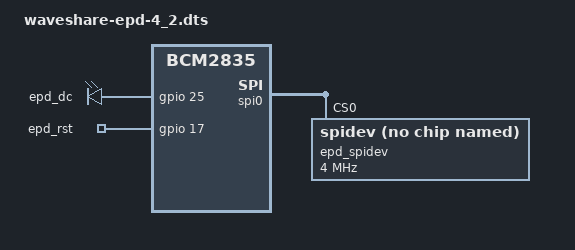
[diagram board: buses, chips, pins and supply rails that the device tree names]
/dts-v1/;
/plugin/;

/*
 * Device Tree Overlay for Waveshare 4.2" E-Paper Display
 *
 * This overlay configures SPI0 and GPIO pins for the Waveshare 4.2" e-paper
 * display module (Rev 2.2) with UC8176/IL0398 controller.
 *
 * Hardware Requirements:
 * - Waveshare 4.2" E-Paper Module (400x300, B/W)
 * - Raspberry Pi Zero W
 *
 * Pin Connections:
 * - VCC:  Pin 1  (3.3V)
 * - GND:  Pin 6  (GND)
 * - DIN:  Pin 19 (GPIO 10 / MOSI)
 * - CLK:  Pin 23 (GPIO 11 / SCLK)
 * - CS:   Pin 24 (GPIO 8  / CE0)
 * - DC:   Pin 22 (GPIO 25)
 * - RST:  Pin 11 (GPIO 17)
 * - BUSY: Pin 18 (GPIO 24)
 *
 * References:
 * - https://www.waveshare.com/wiki/4.2inch_e-Paper_Module
 * - UC8176/IL0398 Controller Datasheet
 */

/ {
	compatible = "brcm,bcm2835";

	fragment@0 {
		target = <&spi0>;
		__overlay__ {
			status = "okay";
			#address-cells = <1>;
			#size-cells = <0>;

			/* SPI0 chip select 0 configuration */
			epd_spidev: spidev@0 {
				compatible = "spidev";
				reg = <0>;	/* CE0 (GPIO 8) */

				/*
				 * SPI frequency: 4 MHz for reliable operation
				 * Display supports up to 10 MHz, but 4 MHz provides
				 * better reliability with longer wires
				 */
				spi-max-frequency = <4000000>;

				/*
				 * SPI Mode 0: CPOL=0, CPHA=0
				 * Clock idle state: LOW
				 * Data sampled on rising edge
				 */
				spi-cpol = <0>;
				spi-cpha = <0>;
			};
		};
	};

	fragment@1 {
		target = <&gpio>;
		__overlay__ {
			epd_pins: epd_pins {
				brcm,pins = <17 24 25>;  /* RST, BUSY, DC */
				brcm,function = <1 0 1>; /* OUT, IN, OUT */
				brcm,pull = <0 2 0>;     /* NONE, UP, NONE */
			};
		};
	};

	/*
	 * Define GPIO pins for e-paper display control
	 * These will be accessed from userspace via /sys/class/gpio or libgpiod
	 */
	fragment@2 {
		target-path = "/";
		__overlay__ {
			epd_gpios {
				compatible = "gpio-leds";
				pinctrl-names = "default";
				pinctrl-0 = <&epd_pins>;

				/*
				 * GPIO 25 - Data/Command (DC)
				 * LOW = Command mode
				 * HIGH = Data mode
				 */
				dc {
					label = "epd_dc";
					gpios = <&gpio 25 0>;  /* GPIO 25, active high */
					default-state = "off";
				};

				/*
				 * GPIO 17 - Reset (RST)
				 * Active LOW reset signal
				 * Typical reset pulse: 10ms low, then high
				 */
				rst {
					label = "epd_rst";
					gpios = <&gpio 17 0>;  /* GPIO 17, active high (inverted in software) */
					default-state = "on";  /* Keep reset deasserted at boot */
				};
			};
		};
	};

	/*
	 * GPIO 24 - BUSY signal
	 * This is an INPUT from the display indicating its status
	 * HIGH = Display is busy (updating)
	 * LOW = Display is ready for commands
	 */
	fragment@3 {
		target = <&gpio>;
		__overlay__ {
			/*
			 * BUSY pin is configured as input with pull-down
			 * Note: The actual BUSY signal will be read from userspace
			 * via GPIO sysfs or libgpiod character device
			 */
			epd_busy_pin: epd_busy_pin {
				brcm,pins = <24>;       /* GPIO 24 */
				brcm,function = <0>;    /* Input */
				brcm,pull = <1>;        /* Pull-down */
			};
		};
	};

	__overrides__ {
		/*
		 * Allow customization of pins and SPI settings via config.txt
		 * Example: dtoverlay=waveshare-epd-4_2,speed=2000000
		 */
		speed = <&epd_spidev>, "spi-max-frequency:0";
		dc_pin = <&epd_pins>, "brcm,pins:8";
		rst_pin = <&epd_pins>, "brcm,pins:0";
		busy_pin = <&epd_busy_pin>, "brcm,pins:0";
	};
};
